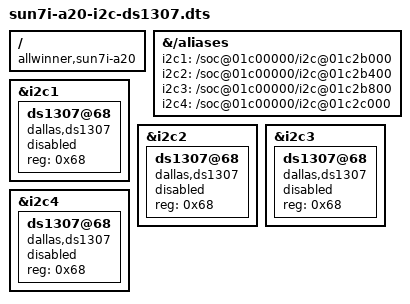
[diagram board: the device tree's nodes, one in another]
/dts-v1/ /plugin/;

/ {
	compatible = "allwinner,sun7i-a20";

	fragment@0 {
		target-path = "/aliases";
		__overlay__ {
			i2c1 = "/soc@01c00000/i2c@01c2b000";
			i2c2 = "/soc@01c00000/i2c@01c2b400";
			i2c3 = "/soc@01c00000/i2c@01c2b800";
			i2c4 = "/soc@01c00000/i2c@01c2c000";
		};
	};

	fragment@1 {
		target = <&i2c1>;
		__overlay__ {
			#address-cells = <1>;
			#size-cells = <0>;
			ds1307@68 {
				compatible = "dallas,ds1307";
				reg = <0x68>;
				status = "disabled";
			};
		};
	};

	fragment@2 {
		target = <&i2c2>;
		__overlay__ {
			#address-cells = <1>;
			#size-cells = <0>;
			ds1307@68 {
				compatible = "dallas,ds1307";
				reg = <0x68>;
				status = "disabled";
			};
		};
	};

	fragment@3 {
		target = <&i2c3>;
		__overlay__ {
			#address-cells = <1>;
			#size-cells = <0>;
			ds1307@68 {
				compatible = "dallas,ds1307";
				reg = <0x68>;
				status = "disabled";
			};
		};
	};

	fragment@4 {
		target = <&i2c4>;
		__overlay__ {
			#address-cells = <1>;
			#size-cells = <0>;
			ds1307@68 {
				compatible = "dallas,ds1307";
				reg = <0x68>;
				status = "disabled";
			};
		};
	};
};
